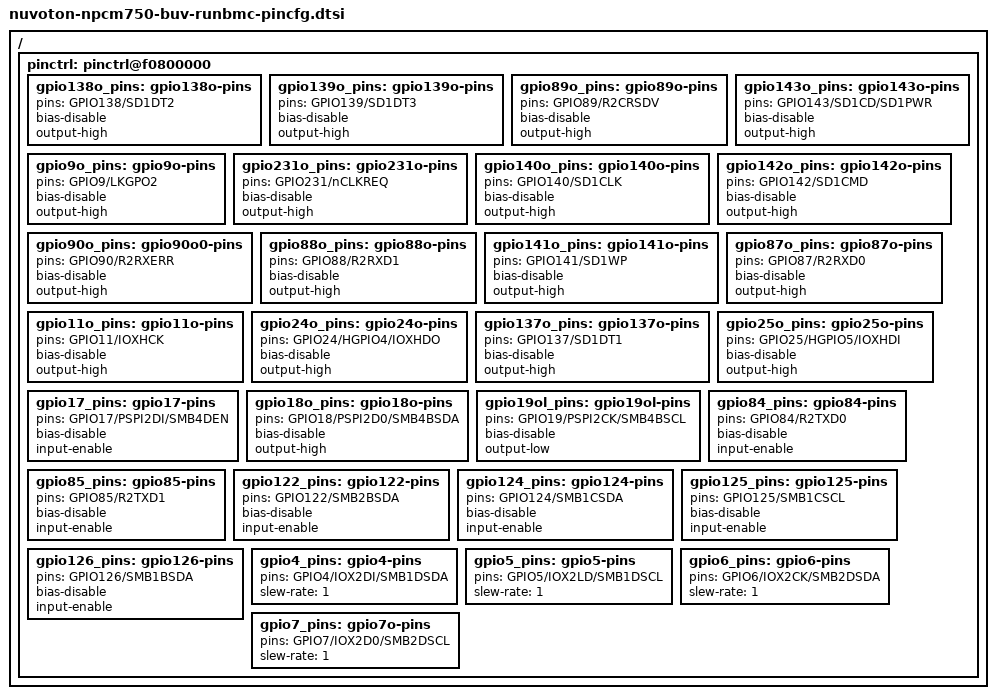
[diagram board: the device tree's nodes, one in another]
// SPDX-License-Identifier: GPL-2.0
// Copyright (c) 2019 Quanta Computer Inc. Samuel.Jiang@quantatw.com

/ {
	pinctrl: pinctrl@f0800000 {
		gpio138o_pins: gpio138o-pins {
			pins = "GPIO138/SD1DT2";
			bias-disable;
			output-high;
		};
		gpio139o_pins: gpio139o-pins {
			pins = "GPIO139/SD1DT3";
			bias-disable;
			output-high;
		};
		gpio89o_pins: gpio89o-pins {
			pins = "GPIO89/R2CRSDV";
			bias-disable;
			output-high;
		};
		gpio143o_pins: gpio143o-pins {
			pins = "GPIO143/SD1CD/SD1PWR";
			bias-disable;
			output-high;
		};
		gpio9o_pins: gpio9o-pins {
			pins = "GPIO9/LKGPO2";
			bias-disable;
			output-high;
		};
		gpio231o_pins: gpio231o-pins {
			pins = "GPIO231/nCLKREQ";
			bias-disable;
			output-high;
		};
		gpio140o_pins: gpio140o-pins {
			pins = "GPIO140/SD1CLK";
			bias-disable;
			output-high;
		};
		gpio142o_pins: gpio142o-pins {
			pins = "GPIO142/SD1CMD";
			bias-disable;
			output-high;
		};
		gpio90o_pins: gpio90o0-pins {
			pins = "GPIO90/R2RXERR";
			bias-disable;
			output-high;
		};
		gpio88o_pins: gpio88o-pins {
			pins = "GPIO88/R2RXD1";
			bias-disable;
			output-high;
		};
		gpio141o_pins: gpio141o-pins {
			pins = "GPIO141/SD1WP";
			bias-disable;
			output-high;
		};
		gpio87o_pins: gpio87o-pins {
			pins = "GPIO87/R2RXD0";
			bias-disable;
			output-high;
		};
		gpio11o_pins: gpio11o-pins {
			pins = "GPIO11/IOXHCK";
			bias-disable;
			output-high;
		};
		gpio24o_pins: gpio24o-pins {
			pins = "GPIO24/HGPIO4/IOXHDO";
			bias-disable;
			output-high;
		};
		gpio137o_pins: gpio137o-pins {
			pins = "GPIO137/SD1DT1";
			bias-disable;
			output-high;
		};
		gpio25o_pins: gpio25o-pins {
			pins = "GPIO25/HGPIO5/IOXHDI";
			bias-disable;
			output-high;
		};
		gpio17_pins: gpio17-pins {
			pins = "GPIO17/PSPI2DI/SMB4DEN";
			bias-disable;
			input-enable;
		};
		gpio18o_pins: gpio18o-pins {
			pins = "GPIO18/PSPI2D0/SMB4BSDA";
			bias-disable;
			output-high;
		};
		gpio19ol_pins: gpio19ol-pins {
			pins = "GPIO19/PSPI2CK/SMB4BSCL";
			bias-disable;
			output-low;
		};
		gpio84_pins: gpio84-pins {
			pins = "GPIO84/R2TXD0";
			bias-disable;
			input-enable;
		};
		gpio85_pins: gpio85-pins {
			pins = "GPIO85/R2TXD1";
			bias-disable;
			input-enable;
		};
		gpio122_pins: gpio122-pins {
			pins = "GPIO122/SMB2BSDA";
			bias-disable;
			input-enable;
		};
		gpio124_pins: gpio124-pins {
			pins = "GPIO124/SMB1CSDA";
			bias-disable;
			input-enable;
		};
		gpio125_pins: gpio125-pins {
			pins = "GPIO125/SMB1CSCL";
			bias-disable;
			input-enable;
		};
		gpio126_pins: gpio126-pins {
			pins = "GPIO126/SMB1BSDA";
			bias-disable;
			input-enable;
		};
		gpio4_pins: gpio4-pins {
			pins = "GPIO4/IOX2DI/SMB1DSDA";
			slew-rate = <1>;
		};
		gpio5_pins: gpio5-pins {
			pins = "GPIO5/IOX2LD/SMB1DSCL";
			slew-rate = <1>;
		};
		gpio6_pins: gpio6-pins {
			pins = "GPIO6/IOX2CK/SMB2DSDA";
			slew-rate = <1>;
		};
		gpio7_pins: gpio7o-pins {
			pins = "GPIO7/IOX2D0/SMB2DSCL";
			slew-rate = <1>;
		};
	};
};
